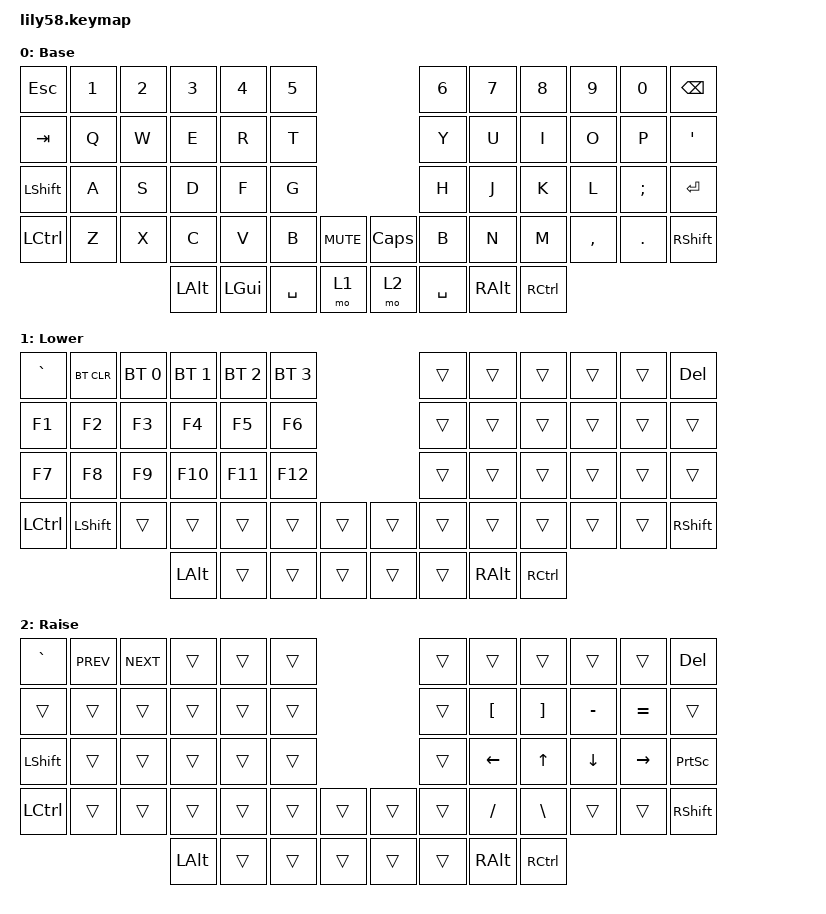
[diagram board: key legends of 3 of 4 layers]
/*
 * Copyright (c) 2020 The ZMK Contributors
 *
 * SPDX-License-Identifier: MIT
 */

#include <behaviors.dtsi>
#include <dt-bindings/zmk/keys.h>
#include <dt-bindings/zmk/bt.h>
#include <dt-bindings/zmk/ext_power.h>
#include <dt-bindings/zmk/pointing.h>
#include <dt-bindings/zmk/rgb.h>

&left_encoder {
    steps = <48>;
};

&sensors {
    triggers-per-rotation = <24>;
    sensors = <&left_encoder &right_encoder>;
};

&msc {
    trigger-period-ms = <8>;
};

&led_strip {
    chain-length = <36>; /* 6 underglow + 30 per-key, one daisy chain */
};

/ {
    behaviors {
        mouse_emu: sensor_rotate_msc {
            compatible = "zmk,behavior-sensor-rotate-var";
            #sensor-binding-cells = <2>;
            bindings = <&msc>, <&msc>;
            tap-ms = <12>;
        };
    };

    conditional_layers {
        compatible = "zmk,conditional-layers";

        adjust_layer {
            if-layers = <1 2>;
            then-layer = <3>;
        };
    };

    keymap {
        compatible = "zmk,keymap";

        default_layer {
        display-name = "Base";
// --------------------------------------------------------------------------------------------------------------------
// |  ESC  |   1   |   2   |   3   |   4   |   5   |                  |   6   |   7   |   8   |   9   |   0   | BSPC  |
// |  TAB  |   Q   |   W   |   E   |   R   |   T   |                  |   Y   |   U   |   I   |   O   |   P   |   '   |
// | SHIFT |   A   |   S   |   D   |   F   |   G   |                  |   H   |   J   |   K   |   L   |   ;   | ENTER |
// |  CTRL |   Z   |   X   |   C   |   V   |   B   |  Mute |  |  Caps |   B   |   N   |   M   |   ,   |   .   | SHIFT |
//                         |  LALT |  GUI  | SPACE | LOWER |  | RAISE | SPACE |  RALT |  CTRL |
            bindings = <
&kp ESC   &kp N1 &kp N2 &kp N3   &kp N4   &kp N5                         &kp N6    &kp N7   &kp N8    &kp N9    &kp N0   &kp BSPC
&kp TAB   &kp Q  &kp W  &kp E    &kp R    &kp T                          &kp Y     &kp U    &kp I     &kp O     &kp P    &kp SQT
&kp LSHFT &kp A  &kp S  &kp D    &kp F    &kp G                          &kp H     &kp J    &kp K     &kp L     &kp SEMI &kp RET
&kp LCTRL &kp Z  &kp X  &kp C    &kp V    &kp B     &kp C_MUTE  &kp CAPS &kp B     &kp N    &kp M     &kp COMMA &kp DOT  &kp RSHFT
                        &kp LALT &kp LGUI &kp SPACE &mo 1       &mo 2    &kp SPACE &kp RALT &kp RCTRL
            >;

            sensor-bindings = <&inc_dec_kp C_VOL_UP C_VOL_DN &mouse_emu MOVE_Y(125) MOVE_Y(-125)>;
        };

        lower_layer {
        display-name = "Lower";
// --------------------------------------------------------------------------------------------------------------------
// |   `   | BTCLR |  BT1  |  BT2  |  BT3  |  BT4  |                  |       |       |       |       |       | DELETE|
// |  F1   |  F2   |  F3   |  F4   |  F5   |  F6   |                  |       |       |       |       |       |       |
// |  F7   |  F8   |  F9   |  F10  |  F11  |  F12  |                  |       |       |       |       |       |       |
// |  CTRL | SHIFT |       |       |       |       |       |  |       |       |       |       |       |       | SHIFT |
//                         |  LALT |       |       |  ~X~  |  |  ~X~  |       |  RALT |  CTRL |
            bindings = <
&kp GRAVE  &bt BT_CLR   &bt BT_SEL 0 &bt BT_SEL 1 &bt BT_SEL 2 &bt BT_SEL 3                 &trans    &trans    &trans    &trans    &trans    &kp DELETE
&kp F1     &kp F2       &kp F3       &kp F4       &kp F5       &kp F6                       &trans    &trans    &trans    &trans    &trans    &trans
&kp F7     &kp F8       &kp F9       &kp F10      &kp F11      &kp F12                      &trans    &trans    &trans    &trans    &trans    &trans
&kp LCTRL  &kp LSHFT    &trans       &trans       &trans       &trans    &trans   &trans    &trans    &trans    &trans    &trans    &trans    &kp RSHFT
                                     &kp LALT     &trans       &trans    &trans   &trans    &trans    &kp RALT  &kp RCTRL
            >;

            sensor-bindings = <&inc_dec_kp C_VOL_UP C_VOL_DN &inc_dec_kp PG_UP PG_DN>;
        };

        raise_layer {
        display-name = "Raise";
// --------------------------------------------------------------------------------------------------------------------
// |   `   | Prev  | Next  | Play  | Bri-  | Bri+  |                  |       |       |       |       |       | DELETE|
// |       |       |       |       |       |       |                  |       |   [   |   ]   |   -   |   +   |       |
// | SHIFT |       |       |       |       |       |                  |       |   <-  |   ^   |   v   |  ->   | PSCRN |
// |  CTRL |       |       |       |       |       |       |  |       |       |   /   |   \   |       |       | SHIFT |
//                         |  LALT |       |       |  ~X~  |  |  ~X~  |       |  RALT |  CTRL |
            bindings = <
&kp GRAVE  &kp K_PREV   &kp C_NEXT   &trans       &trans       &trans                       &trans    &trans    &trans    &trans    &trans    &kp DELETE
&trans     &trans       &trans       &trans       &trans       &trans                       &trans    &kp LBKT  &kp RBKT  &kp MINUS &kp EQUAL &trans
&kp LSHFT  &trans       &trans       &trans       &trans       &trans                       &trans    &kp LEFT  &kp UP    &kp DOWN  &kp RIGHT &kp PSCRN
&kp LCTRL  &trans       &trans       &trans       &trans       &trans    &trans   &trans    &trans    &kp FSLH  &kp BSLH  &trans    &trans    &kp RSHFT
                                     &kp LALT     &trans       &trans    &trans   &trans    &trans    &kp RALT  &kp RCTRL
            >;

            sensor-bindings = <&inc_dec_kp C_VOL_UP C_VOL_DN &mouse_emu MOVE_X(-125) MOVE_X(125)>;
        };

        adjust_layer {
        display-name = "Adjust";
// ---------------------------------------------------------------------------------------------------------------------
// | BTCLR |  BT1  |  BT2  |  BT3  |  BT4  |  BT5  |                  |       |       |       |       |       |       |
// | EXTPWR|  Hue- |  Hue+ |  Sat- |  Sat+ |  Eff+ |                  |       |       |       |       |       |       |
// |       |  Bri- |  Bri+ | Sped- | Sped+ |  Eff- |                  |       |       |       |       |       |       |
// |       |       |       |       | Toggl | MINTO |       |  |       |       |       |       |       |       |       |
//                         |       |       |       |  ~X~  |  |  ~X~  |       |       |       | 
            bindings = <
&bt BT_CLR         &bt BT_SEL 0    &bt BT_SEL 1     &bt BT_SEL 2     &bt BT_SEL 3     &bt BT_SEL 4                        &trans  &trans  &trans  &trans  &trans  &trans
&ext_power EP_TOG  &rgb_ug RGB_HUD &rgb_ug RGB_HUI  &rgb_ug RGB_SAD  &rgb_ug RGB_SAI  &rgb_ug RGB_EFF                     &trans  &trans  &trans  &trans  &trans  &trans
&trans             &rgb_ug RGB_BRD &rgb_ug RGB_BRI  &rgb_ug RGB_SPD  &rgb_ug RGB_SPI  &rgb_ug RGB_EFR                     &trans  &trans  &trans  &trans  &trans  &trans
&trans             &trans          &trans  &trans   &rgb_ug RGB_TOG  &rgb_ug RGB_COLOR_HSB(159,33,95)  &trans   &trans    &trans  &trans  &trans  &trans  &trans  &trans
                                   &trans           &trans           &trans           &trans           &trans   &trans    &trans  &trans  &trans  &trans 
            >;
            sensor-bindings = <&inc_dec_kp C_VOL_UP C_VOL_DN>;
        };
    };
        extra { status = "reserved"; };
};
